# STM32H735ZGT6 register map
File version: 1.0
STM32H735AGI6,STM32H735IGK3,STM32H735IGK6,STM32H735IGK7,STM32H735IGT3,STM32H735IGT6,STM32H735IGT7,STM32H735RGV6,STM32H735VGH6,STM32H735VGT6,STM32H735VGY6,STM32H735ZGT6
Registers are 32-bit, access not given, reset 0x0 unless marked. A register's access mark holds for its fields unless they carry their own. Offsets are from the block's base; lines under a group give offsets from that group; [hi:lo] are bit positions; {n}, {i} and the like mark numbered series; 'fields as' and 'values as' point back to an identical list; <NAME> marks a mode.

## Memory map
0x40000000 TIM2
0x40000400 TIM3
0x40000800 TIM4
0x40000C00 TIM5
0x40001000 TIM6
0x40001400 TIM7
0x40001800 TIM12
0x40001C00 TIM13
0x40002000 TIM14
0x40002400 LPTIM1
0x40003800 SPI2
0x40003C00 SPI3
0x40004000 SPDIFRX
0x40004400 USART2
0x40004800 USART3
0x40004C00 UART4
0x40005000 UART5
0x40005400 I2C1
0x40005800 I2C2
0x40005C00 I2C3
0x40006400 I2C5
0x40006C00 CEC
0x40007400 DAC1
0x40007800 UART7
0x40007C00 UART8
0x40008400 CRS
0x40008800 SWPMI1
0x40009000 OPAMP
0x40009000 OPAMP1
0x40009010 OPAMP2
0x40009400 MDIOS
0x4000A000 FDCAN1
0x4000A400 FDCAN2
0x4000A800 FDCAN_CCU
0x4000D400 FDCAN3
0x4000E000 TIM23
0x4000E400 TIM24
0x40010000 TIM1
0x40010400 TIM8
0x40011000 USART1
0x40011400 USART6
0x40011800 UART9
0x40011C00 USART10
0x40013000 SPI1
0x40013400 SPI4
0x40014000 TIM15
0x40014400 TIM16
0x40014800 TIM17
0x40015000 SPI5
0x40015800 SAI1
0x40017800 DFSDM1
0x40020000 DMA1
0x40020400 DMA2
0x40020800 DMAMUX1
0x40022000 ADC1
0x40022100 ADC2
0x40022300 ADC12_COMMON
0x40028000 ETH
0x40040000 USB1_OTG_HS
0x48020000 DCMI
0x48020400 PSSI
0x48021000 CRYP
0x48021400 HASH
0x48021710 HASH_DIGEST
0x48021800 RNG
0x48022400 SDMMC2
0x48022800 DLYB_SDMMC2
0x48023000 RAMECC2
0x48024000 FMAC
0x48024400 CORDIC
0x50001000 LTDC
0x50003000 WWDG1
0x51000000 GPV
0x52000000 MDMA
0x52001000 DMA2D
0x52002000 FLASH
0x52004000 FMC_Bank1_R
0x52004060 FMC_Bank2_R
0x52004080 FMC_Bank3_R
0x52004104 FMC_Bank1E_R
0x52004140 FMC_Bank5_6_R
0x52005000 OCTOSPI1
0x52006000 DLYB_OCTOSPI1
0x52007000 SDMMC1
0x52008000 DLYB_SDMMC1
0x52009000 RAMECC1
0x5200A000 OCTOSPI2
0x5200B000 DLYB_OCTOSPI2
0x5200B400 OCTOSPIM
0x5200B800 OTFDEC1
0x5200B820 OTFDEC1_REGION1
0x5200B850 OTFDEC1_REGION2
0x5200B880 OTFDEC1_REGION3
0x5200B8B0 OTFDEC1_REGION4
0x5200BC00 OTFDEC2
0x5200BC20 OTFDEC2_REGION1
0x5200BC50 OTFDEC2_REGION2
0x5200BC80 OTFDEC2_REGION3
0x5200BCB0 OTFDEC2_REGION4
0x58000000 EXTI
0x58000080 EXTI_D1
0x580000C0 EXTI_D2
0x58000400 SYSCFG
0x58000C00 LPUART1
0x58001400 SPI6
0x58001C00 I2C4
0x58002400 LPTIM2
0x58002800 LPTIM3
0x58002C00 LPTIM4
0x58003000 LPTIM5
0x58003800 COMP12
0x5800380C COMP1
0x58003810 COMP2
0x58003810 COMP12_COMMON
0x58003C00 VREFBUF
0x58004000 RTC
0x58004800 IWDG1
0x58005400 SAI4
0x58006800 DTS
0x58020000 GPIOA
0x58020400 GPIOB
0x58020800 GPIOC
0x58020C00 GPIOD
0x58021000 GPIOE
0x58021400 GPIOF
0x58021800 GPIOG
0x58021C00 GPIOH
0x58022400 GPIOJ
0x58022800 GPIOK
0x58024400 RCC
0x58024800 PWR
0x58024C00 CRC
0x58025400 BDMA
0x58025800 DMAMUX2
0x58026000 ADC3
0x58026300 ADC3_COMMON
0x58026400 HSEM
0x58026500 HSEM_COMMON
0x58027000 RAMECC3
0x5C001000 DBGMCU

## TIM2
Base 0x40000000
Same registers: TIM3 0x40000400, TIM4 0x40000800, TIM5 0x40000C00, TIM6 0x40001000, TIM7 0x40001400, TIM12 0x40001800, TIM13 0x40001C00, TIM14 0x40002000, TIM23 0x4000E000, TIM24 0x4000E400, TIM1 0x40010000, TIM8 0x40010400, TIM15 0x40014000, TIM16 0x40014400, TIM17 0x40014800
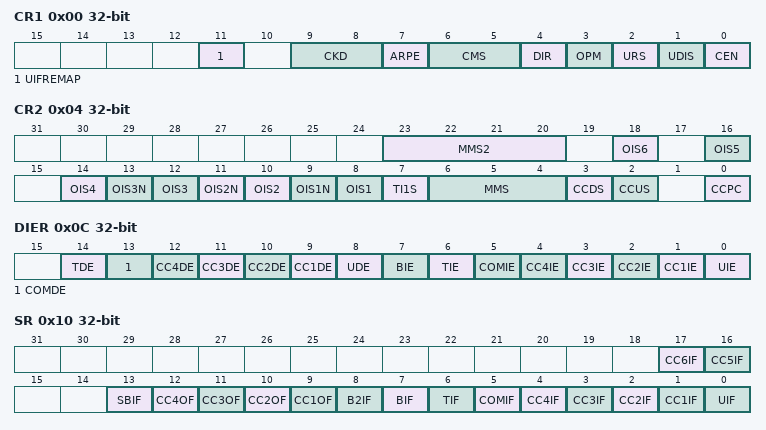
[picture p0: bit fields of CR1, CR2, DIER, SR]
0x00 CR1
  [11] UIFREMAP, [9:8] CKD, [7] ARPE, [6:5] CMS, [4] DIR, [3] OPM, [2] URS, [1] UDIS, [0] CEN
0x04 CR2
  [23:20] MMS2, [2n+6] OIS{n} (n=1..6), [13] OIS3N, [11] OIS2N, [9] OIS1N, [7] TI1S, [6:4] MMS, [3] CCDS, [2] CCUS, [0] CCPC
0x08 SMCR
  [15] ETP, [14] ECE, [13:12] ETPS, [11:8] ETF, [7] MSM, [21:4] TS, [16:0] SMS
0x0C DIER
  [14] TDE, [13] COMDE, [n+8] CC{n}DE (n=1..4), [8] UDE, [7] BIE, [6] TIE, [5] COMIE, [n] CC{n}IE (n=1..4), [0] UIE
0x10 SR
  [17] CC6IF, [16] CC5IF, [13] SBIF, [n+8] CC{n}OF (n=1..4), [8] B2IF, [7] BIF, [6] TIF, [5] COMIF, [n] CC{n}IF (n=1..4), [0] UIF
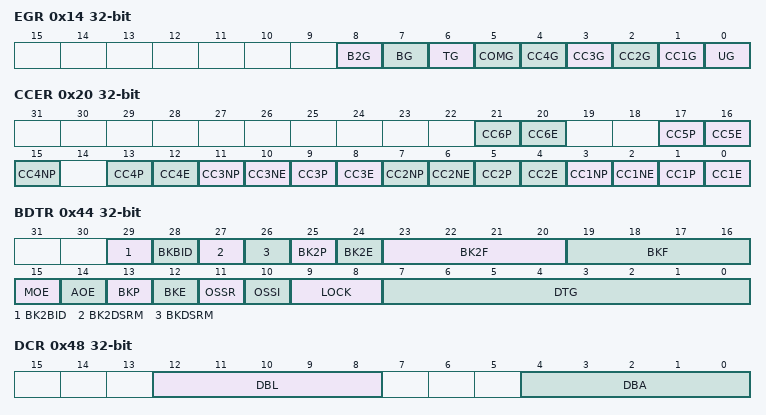
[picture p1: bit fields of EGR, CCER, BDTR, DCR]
0x14 EGR
  [8] B2G, [7] BG, [6] TG, [5] COMG, [n] CC{n}G (n=1..4), [0] UG
0x18 CCMR1
  [15] OC2CE, [24:12] OC2M, [11] OC2PE, [10] OC2FE, [9:8] CC2S, [7] OC1CE, [16:4] OC1M, [3] OC1PE, [2] OC1FE, [1:0] CC1S
0x1C CCMR2
  [15] OC4CE, [24:12] OC4M, [11] OC4PE, [10] OC4FE, [9:8] CC4S, [7] OC3CE, [16:4] OC3M, [3] OC3PE, [2] OC3FE, [1:0] CC3S
0x20 CCER
  [4n-3] CC{n}P (n=1..6), [4n-4] CC{n}E (n=1..6), [4n-1] CC{n}NP (n=1..4), [10] CC3NE, [6] CC2NE, [2] CC1NE
0x24 CNT
  [31] UIFCPY, [31:0] CNT
0x28 PSC
  [15:0] PSC
0x2C ARR
0x30 RCR
  [7:0] REP
{0x30+4i} CCR{i} (i=1..4)
  [15:0] CCR{i}
0x44 BDTR
  [29] BK2BID, [28] BKBID, [27] BK2DSRM, [26] BKDSRM, [25] BK2P, [24] BK2E, [23:20] BK2F, [19:16] BKF, [15] MOE, [14] AOE, [13] BKP, [12] BKE, [11] OSSR, [10] OSSI, [9:8] LOCK, [7:0] DTG
0x48 DCR
  [12:8] DBL, [4:0] DBA
0x4C DMAR
  [15:0] DMAB
0x54 CCMR3
  [15] OC6CE, [24:12] OC6M, [11] OC6PE, [10] OC6FE, [7] OC5CE, [16:4] OC5M, [3] OC5PE, [2] OC5FE
0x58 CCR5
  [31] GC5C3, [30] GC5C2, [29] GC5C1, [31:0] CCR5
0x5C CCR6
  [15:0] CCR6
0x60 AF1
0x64 AF2
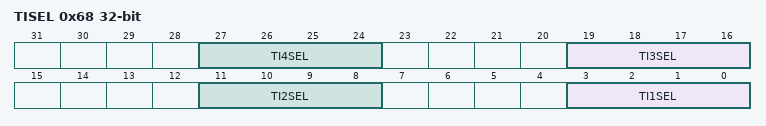
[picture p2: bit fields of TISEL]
0x68 TISEL
  [8n-5:8n-8] TI{n}SEL (n=1..4)
